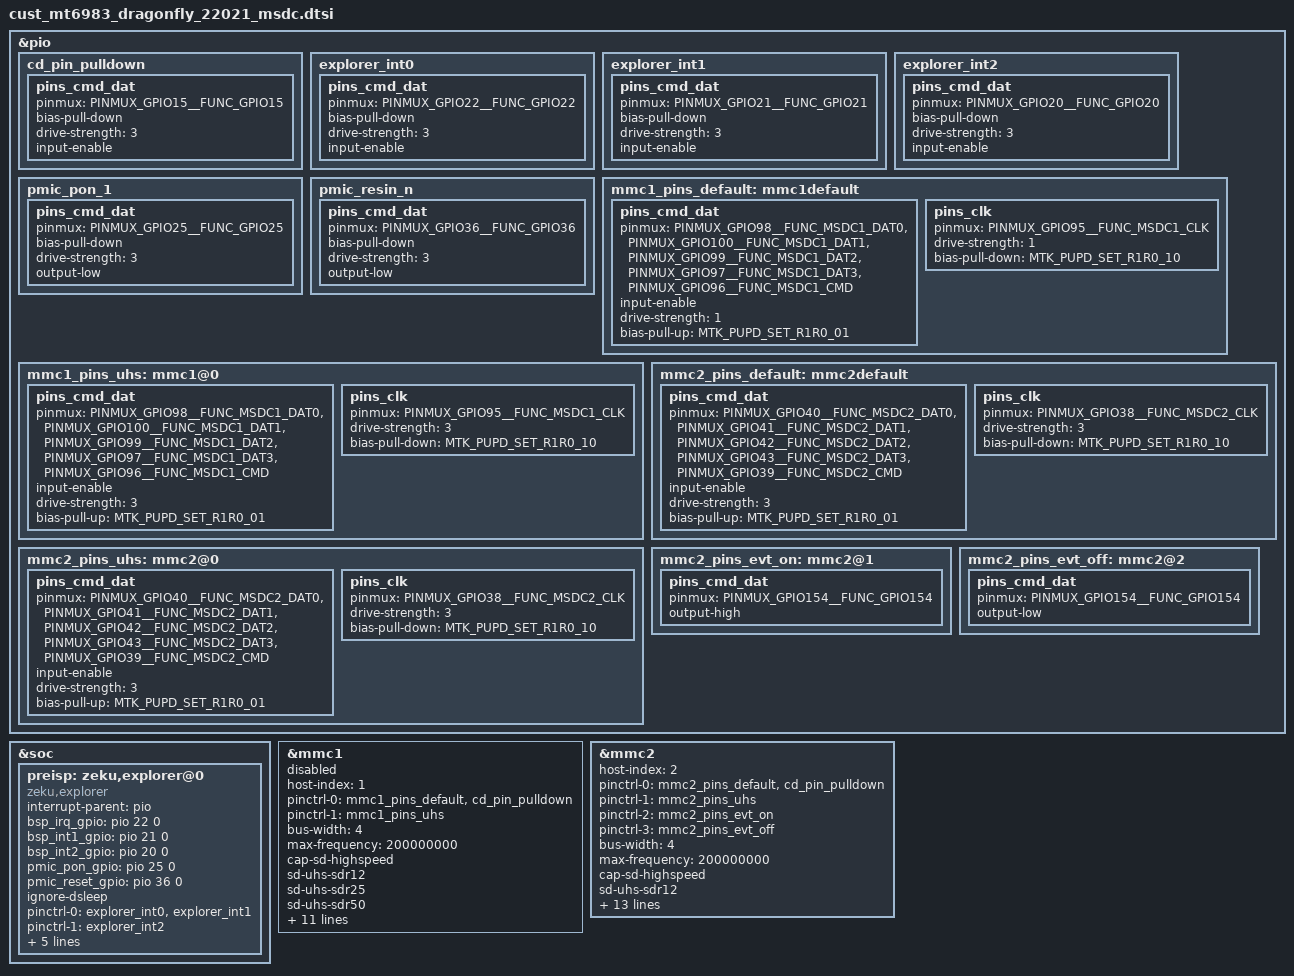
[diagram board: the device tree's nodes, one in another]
// SPDX-License-Identifier: GPL-2.0
/*
 * Copyright (c) 2020 MediaTek Inc.
 */
/********************************************
 * MT6895 MSDC DTSI File
 ********************************************/
#include <dt-bindings/gpio/gpio.h>

//#ifdef /*OPLUS_FEATURE_TP_BASIC */

&pio {
	cd_pin_pulldown: cd_pin_pulldown {
		pins_cmd_dat {
			pinmux = <PINMUX_GPIO15__FUNC_GPIO15>;
			bias-pull-down;
			drive-strength = <3>;
			input-enable;
		};
	};
	explorer_int0: explorer_int0 {
		pins_cmd_dat {
			pinmux = <PINMUX_GPIO22__FUNC_GPIO22>;
			bias-pull-down;
			drive-strength = <3>;
			input-enable;
		};
	};
	explorer_int1: explorer_int1 {
                pins_cmd_dat {
					pinmux = <PINMUX_GPIO21__FUNC_GPIO21>;
					bias-pull-down;
					drive-strength = <3>;
					input-enable;
                };
        };
	explorer_int2: explorer_int2 {
                pins_cmd_dat {
					pinmux = <PINMUX_GPIO20__FUNC_GPIO20>;
					bias-pull-down;
					drive-strength = <3>;
					input-enable;
                };
        };
	pmic_pon_1: pmic_pon_1 {
		pins_cmd_dat {
			pinmux = <PINMUX_GPIO25__FUNC_GPIO25>;
			bias-pull-down;
			drive-strength = <3>;
			output-low;
		};
	};
	pmic_resin_n: pmic_resin_n {
		pins_cmd_dat {
			pinmux = <PINMUX_GPIO36__FUNC_GPIO36>;
			bias-pull-down;
			drive-strength = <3>;
			output-low;
		};
	};
};

&soc {
	preisp: zeku,explorer@0 {
		compatible = "zeku,explorer";
		interrupt-parent = <&pio>;
		bsp_irq_gpio = <&pio 22 0>;
		bsp_int1_gpio = <&pio 21 0>;
		bsp_int2_gpio = <&pio 20 0>;
		pmic_pon_gpio = <&pio 25 0>;
		pmic_reset_gpio = <&pio 36 0>;
		ignore-dsleep; //modify the sleep  ignore
		pinctrl-names = "default";
		pinctrl-0 = <&explorer_int0>, <&explorer_int1>;
		pinctrl-1 = <&explorer_int2>;
		pinctrl-2 = <&pmic_pon_1>;
		pinctrl-3 = <&pmic_resin_n>;
		explorer,clk-drive-strength = <2>;
		explorer,cmd-drive-strength = <2>;
		explorer,data-drive-strength = <2>;
	};
};

&mmc1 {
	host-index = <1>;
	status = "disabled";
	pinctrl-names = "default", "state_uhs";
	pinctrl-0 = <&mmc1_pins_default &cd_pin_pulldown>;
	pinctrl-1 = <&mmc1_pins_uhs>;
	bus-width = <4>;
	max-frequency = <200000000>;
	cap-sd-highspeed;
	sd-uhs-sdr12;
	sd-uhs-sdr25;
	sd-uhs-sdr50;
	sd-uhs-sdr104;
	sd-uhs-ddr50;
	cd-debounce-delay-ms = <1>;
	cd-gpios = <&pio 15 GPIO_ACTIVE_HIGH>;
	ocr-voltage = <0x00FFFF00>;
	vqmmc-supply = <&mt6363_vio18>;
	no-mmc;
	no-sd;
	cap-sdio-irq;
	filter_enable = <1>;
	explorer_support = <1>;
};

&mmc2 {
	host-index = <2>;
	status = "okay";
	pinctrl-names = "default", "state_uhs", "evt_on", "evt_off";
	pinctrl-0 = <&mmc2_pins_default &cd_pin_pulldown>;
	pinctrl-1 = <&mmc2_pins_uhs>;
	pinctrl-2 = <&mmc2_pins_evt_on>;
	pinctrl-3 = <&mmc2_pins_evt_off>;
	bus-width = <4>;
	max-frequency = <200000000>;
	cap-sd-highspeed;
	sd-uhs-sdr12;
	sd-uhs-sdr25;
	sd-uhs-sdr50;
	sd-uhs-sdr104;
	sd-uhs-ddr50;
	cd-debounce-delay-ms = <1>;
	cd-gpios = <&pio 15 GPIO_ACTIVE_HIGH>;
	ocr-voltage = <0x00FFFF00>;
	vqmmc-supply = <&mt6363_vio18>;
	no-mmc;
	no-sd;
	cap-sdio-irq;
	filter_enable = <1>;
	explorer_support = <1> ;
};

&pio {
	mmc1_pins_default: mmc1default {
		pins_cmd_dat {
			pinmux = <PINMUX_GPIO98__FUNC_MSDC1_DAT0>,
				<PINMUX_GPIO100__FUNC_MSDC1_DAT1>,
				<PINMUX_GPIO99__FUNC_MSDC1_DAT2>,
				<PINMUX_GPIO97__FUNC_MSDC1_DAT3>,
				<PINMUX_GPIO96__FUNC_MSDC1_CMD>;
			input-enable;
			drive-strength = <1>;
			bias-pull-up = <MTK_PUPD_SET_R1R0_01>;
		};

		pins_clk {
			pinmux = <PINMUX_GPIO95__FUNC_MSDC1_CLK>;
			drive-strength = <1>;
			bias-pull-down = <MTK_PUPD_SET_R1R0_10>;
		};
	};
	mmc1_pins_uhs: mmc1@0{
		pins_cmd_dat {
			pinmux = <PINMUX_GPIO98__FUNC_MSDC1_DAT0>,
				<PINMUX_GPIO100__FUNC_MSDC1_DAT1>,
				<PINMUX_GPIO99__FUNC_MSDC1_DAT2>,
				<PINMUX_GPIO97__FUNC_MSDC1_DAT3>,
				<PINMUX_GPIO96__FUNC_MSDC1_CMD>;
			input-enable;
			drive-strength = <3>;
			bias-pull-up = <MTK_PUPD_SET_R1R0_01>;
		};

		pins_clk {
			pinmux = <PINMUX_GPIO95__FUNC_MSDC1_CLK>;
			drive-strength = <3>;
			bias-pull-down = <MTK_PUPD_SET_R1R0_10>;
		};
	};

	mmc2_pins_default: mmc2default {
		pins_cmd_dat {
			pinmux = <PINMUX_GPIO40__FUNC_MSDC2_DAT0>,
				<PINMUX_GPIO41__FUNC_MSDC2_DAT1>,
				<PINMUX_GPIO42__FUNC_MSDC2_DAT2>,
				<PINMUX_GPIO43__FUNC_MSDC2_DAT3>,
				<PINMUX_GPIO39__FUNC_MSDC2_CMD>;
			input-enable;
			drive-strength = <3>;
			bias-pull-up = <MTK_PUPD_SET_R1R0_01>;
		};
		pins_clk {
			pinmux = <PINMUX_GPIO38__FUNC_MSDC2_CLK>;
			drive-strength = <3>;
			bias-pull-down = <MTK_PUPD_SET_R1R0_10>;
		};
	};
	mmc2_pins_uhs: mmc2@0{
		pins_cmd_dat {
			pinmux = <PINMUX_GPIO40__FUNC_MSDC2_DAT0>,
				<PINMUX_GPIO41__FUNC_MSDC2_DAT1>,
				<PINMUX_GPIO42__FUNC_MSDC2_DAT2>,
				<PINMUX_GPIO43__FUNC_MSDC2_DAT3>,
				<PINMUX_GPIO39__FUNC_MSDC2_CMD>;
			input-enable;
			drive-strength = <3>;
			bias-pull-up = <MTK_PUPD_SET_R1R0_01>;
		};
		pins_clk {
			pinmux = <PINMUX_GPIO38__FUNC_MSDC2_CLK>;
			drive-strength = <3>;
			bias-pull-down = <MTK_PUPD_SET_R1R0_10>;
		};
	};
	mmc2_pins_evt_on: mmc2@1{
		pins_cmd_dat {
			pinmux = <PINMUX_GPIO154__FUNC_GPIO154>;
			output-high;
		};
	};
	mmc2_pins_evt_off: mmc2@2{
		pins_cmd_dat {
			pinmux = <PINMUX_GPIO154__FUNC_GPIO154>;
			output-low;
		};
	};
};
